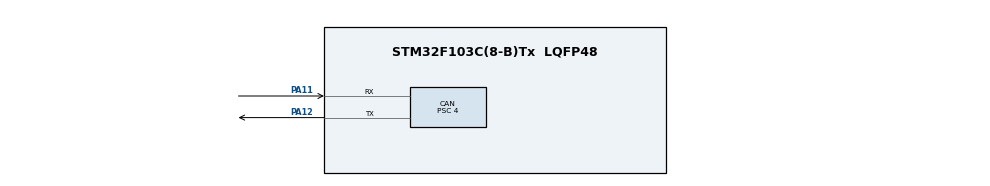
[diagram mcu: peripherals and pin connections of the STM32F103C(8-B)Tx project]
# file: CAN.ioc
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CAN.AutoBusOff=ENABLE
CAN.AutoRetransmission=ENABLE
CAN.BS1=CAN_BS1_13TQ
CAN.BS2=CAN_BS2_2TQ
CAN.CalculateBaudRate=125000
CAN.CalculateTimeBit=8000
CAN.CalculateTimeQuantum=500.0
CAN.Prescaler=4
CAN.SJW=CAN_SJW_1TQ
Mcu.Family=STM32F1
Mcu.Name=STM32F103C(8-B)Tx
Mcu.Package=LQFP48
NVIC.PriorityGroup=NVIC_PRIORITYGROUP_4
PA11.Mode=CAN_Activate
PA11.Signal=CAN_RX
PA12.Mode=CAN_Activate
PA12.Signal=CAN_TX
PA13.Mode=Serial_Wire
PA13.Signal=SYS_JTMS-SWDIO
PA14.Mode=Serial_Wire
PA14.Signal=SYS_JTCK-SWCLK
ProjectManager.HeapSize=0x200
ProjectManager.StackSize=0x400
ProjectManager.TargetToolchain=CMake
RCC.APB1Freq_Value=8000000
RCC.APB2Freq_Value=8000000
board=custom

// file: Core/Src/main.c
/* USER CODE BEGIN Header */
/**
  ******************************************************************************
  * @file           : main.c
  * @brief          : Main program body
  ******************************************************************************
  * @attention
  *
  * Copyright (c) 2026 STMicroelectronics.
  * All rights reserved.
  *
  * This software is licensed under terms that can be found in the LICENSE file
  * in the root directory of this software component.
  * If no LICENSE file comes with this software, it is provided AS-IS.
  *
  ******************************************************************************
  */
/* USER CODE END Header */
#include "main.h"

/* USER CODE BEGIN Includes */
#include "log.h"

/* USER CODE END Includes */

/* USER CODE BEGIN PD */
#define CAN_TX_ID 0x200U
#define CAN_RX_ID 0x201U
#define CAN_TX_PERIOD_MS 1000U

/* USER CODE END PD */

CAN_HandleTypeDef hcan;

/* USER CODE BEGIN PV */
static uint8_t message_number;
static uint32_t last_recovery_ms;
static uint32_t last_tx_ms;
static uint8_t bus_off_reported;

/* USER CODE END PV */

void SystemClock_Config(void);
static void MX_GPIO_Init(void);
static void MX_CAN_Init(void);
/* USER CODE BEGIN PFP */
static void CAN_ConfigureAndStart(void);
static void CAN_Service(void);
static void CAN_LogFrame(const char *direction, uint32_t id, uint32_t dlc,
                         const uint8_t *data);

/* USER CODE END PFP */

int main(void)
{

  /* MCU Configuration--------------------------------------------------------*/

  /* Reset of all peripherals, Initializes the Flash interface and the Systick. */
  HAL_Init();

  /* USER CODE BEGIN Init */
  log_init();
  log_println("[BOOT] STM32 CAN demo");

  /* USER CODE END Init */

  /* Configure the system clock */
  SystemClock_Config();

  /* Initialize all configured peripherals */
  MX_GPIO_Init();
  MX_CAN_Init();
  /* USER CODE BEGIN 2 */
  CAN_ConfigureAndStart();
  log_println("[CAN] started 125 kbit/s, TX=0x200 RX=0x201, period=1000 ms");

  /* USER CODE END 2 */

  /* Infinite loop */
  while (1)
  {

    /* USER CODE BEGIN 3 */
    CAN_Service();
  }
  /* USER CODE END 3 */
}

void SystemClock_Config(void)
{
  RCC_OscInitTypeDef RCC_OscInitStruct = {0};
  RCC_ClkInitTypeDef RCC_ClkInitStruct = {0};

  /** Initializes the RCC Oscillators according to the specified parameters
  * in the RCC_OscInitTypeDef structure.
  */
  RCC_OscInitStruct.OscillatorType = RCC_OSCILLATORTYPE_HSI;
  RCC_OscInitStruct.HSIState = RCC_HSI_ON;
  RCC_OscInitStruct.HSICalibrationValue = RCC_HSICALIBRATION_DEFAULT;
  RCC_OscInitStruct.PLL.PLLState = RCC_PLL_NONE;
  if (HAL_RCC_OscConfig(&RCC_OscInitStruct) != HAL_OK)
  {
    Error_Handler();
  }

  /** Initializes the CPU, AHB and APB buses clocks
  */
  RCC_ClkInitStruct.ClockType = RCC_CLOCKTYPE_HCLK|RCC_CLOCKTYPE_SYSCLK
                              |RCC_CLOCKTYPE_PCLK1|RCC_CLOCKTYPE_PCLK2;
  RCC_ClkInitStruct.SYSCLKSource = RCC_SYSCLKSOURCE_HSI;
  RCC_ClkInitStruct.AHBCLKDivider = RCC_SYSCLK_DIV1;
  RCC_ClkInitStruct.APB1CLKDivider = RCC_HCLK_DIV1;
  RCC_ClkInitStruct.APB2CLKDivider = RCC_HCLK_DIV1;

  if (HAL_RCC_ClockConfig(&RCC_ClkInitStruct, FLASH_LATENCY_0) != HAL_OK)
  {
    Error_Handler();
  }
}

static void MX_CAN_Init(void)
{

  hcan.Instance = CAN1;
  /* 8 MHz APB1 / (4 * (1 + 13 + 2)) = 125 kbit/s. */
  hcan.Init.Prescaler = 4;
  hcan.Init.Mode = CAN_MODE_NORMAL;
  hcan.Init.SyncJumpWidth = CAN_SJW_1TQ;
  hcan.Init.TimeSeg1 = CAN_BS1_13TQ;
  hcan.Init.TimeSeg2 = CAN_BS2_2TQ;
  hcan.Init.TimeTriggeredMode = DISABLE;
  hcan.Init.AutoBusOff = ENABLE;
  hcan.Init.AutoWakeUp = DISABLE;
  hcan.Init.AutoRetransmission = ENABLE;
  hcan.Init.ReceiveFifoLocked = DISABLE;
  hcan.Init.TransmitFifoPriority = DISABLE;
  if (HAL_CAN_Init(&hcan) != HAL_OK)
  {
    Error_Handler();
  }

}

static void MX_GPIO_Init(void)
{

  /* GPIO Ports Clock Enable */
  __HAL_RCC_GPIOA_CLK_ENABLE();

}

/* USER CODE BEGIN 4 */
static void CAN_ConfigureAndStart(void)
{
  CAN_FilterTypeDef filter = {0};

  /* 32-bit mask filter: standard data frame with ID 0x201 only. */
  filter.FilterBank = 0;
  filter.FilterMode = CAN_FILTERMODE_IDMASK;
  filter.FilterScale = CAN_FILTERSCALE_32BIT;
  filter.FilterIdHigh = (uint16_t)(CAN_RX_ID << 5);
  filter.FilterIdLow = 0;
  filter.FilterMaskIdHigh = (uint16_t)(0x7FFU << 5);
  filter.FilterMaskIdLow = 0x0006U; /* match IDE and RTR */
  filter.FilterFIFOAssignment = CAN_FILTER_FIFO0;
  filter.FilterActivation = ENABLE;
  if (HAL_CAN_ConfigFilter(&hcan, &filter) != HAL_OK)
  {
    log_print("[CAN] filter failed, HAL error=");
    log_print_u32_hex(HAL_CAN_GetError(&hcan));
    log_println("");
    Error_Handler();
  }
  log_print("[CAN] before start: PA11=");
  log_print_u32_dec(HAL_GPIO_ReadPin(GPIOA, GPIO_PIN_11));
  log_print(" MSR=");
  log_print_u32_hex(CAN1->MSR);
  log_print(" CAN_REMAP=");
  log_print_u32_hex(AFIO->MAPR & AFIO_MAPR_CAN_REMAP);
  log_print(" BTR=");
  log_print_u32_hex(CAN1->BTR);
  log_println("");
  if (HAL_CAN_Start(&hcan) != HAL_OK)
  {
    log_print("[CAN] start failed, HAL error=");
    log_print_u32_hex(HAL_CAN_GetError(&hcan));
    log_print(" PA11=");
    log_print_u32_dec(HAL_GPIO_ReadPin(GPIOA, GPIO_PIN_11));
    log_print(" MCR=");
    log_print_u32_hex(CAN1->MCR);
    log_print(" MSR=");
    log_print_u32_hex(CAN1->MSR);
    log_print(" ESR=");
    log_print_u32_hex(CAN1->ESR);
    log_println("");
    Error_Handler();
  }
}

static void CAN_Service(void)
{
  CAN_RxHeaderTypeDef rx;
  CAN_TxHeaderTypeDef tx = {0};
  uint8_t received[8] = {0};
  uint8_t payload[8];
  uint32_t mailbox;
  uint32_t now = HAL_GetTick();
  uint32_t dlc;

  /* HAL error flags are sticky; ESR reports the current bus-off state. */
  if ((hcan.Instance->ESR & CAN_ESR_BOFF) != 0U)
  {
    if (bus_off_reported == 0U)
    {
      log_print("[CAN] bus off, HAL error=");
      log_print_u32_hex(HAL_CAN_GetError(&hcan));
      log_println("");
      bus_off_reported = 1U;
    }
    if ((now - last_recovery_ms) >= 1000U)
    {
      last_recovery_ms = now;
      if (HAL_CAN_Stop(&hcan) == HAL_OK)
      {
        if (HAL_CAN_Start(&hcan) == HAL_OK)
        {
          log_println("[CAN] restart requested");
        }
        else
        {
          log_println("[CAN] restart failed");
        }
      }
    }
    return;
  }
  if (bus_off_reported != 0U)
  {
    log_println("[CAN] bus active again");
    bus_off_reported = 0U;
  }

  while (HAL_CAN_GetRxFifoFillLevel(&hcan, CAN_RX_FIFO0) != 0U)
  {
    if (HAL_CAN_GetRxMessage(&hcan, CAN_RX_FIFO0, &rx, received) != HAL_OK)
    {
      log_print("[CAN] RX failed, HAL error=");
      log_print_u32_hex(HAL_CAN_GetError(&hcan));
      log_println("");
      break;
    }
    CAN_LogFrame("RX", rx.IDE == CAN_ID_STD ? rx.StdId : rx.ExtId,
                 rx.DLC, received);
  }

  if ((now - last_tx_ms) < CAN_TX_PERIOD_MS)
  {
    return;
  }
  last_tx_ms = now;
  if (HAL_CAN_GetTxMailboxesFreeLevel(&hcan) == 0U)
  {
    log_print("[CAN] TX mailboxes full; frame skipped, ESR=");
    log_print_u32_hex(CAN1->ESR);
    log_print(" TSR=");
    log_print_u32_hex(CAN1->TSR);
    log_print(" PA11=");
    log_print_u32_dec(HAL_GPIO_ReadPin(GPIOA, GPIO_PIN_11));
    log_println("");
    return;
  }

  payload[0] = 'h';
  payload[1] = 'e';
  payload[2] = 'l';
  payload[3] = 'l';
  payload[4] = 'o';
  payload[5] = ' ';
  if (message_number >= 10U)
  {
    payload[6] = (uint8_t)('0' + message_number / 10U);
    payload[7] = (uint8_t)('0' + message_number % 10U);
    dlc = 8U;
  }
  else
  {
    payload[6] = (uint8_t)('0' + message_number);
    dlc = 7U;
  }
  tx.StdId = CAN_TX_ID;
  tx.IDE = CAN_ID_STD;
  tx.RTR = CAN_RTR_DATA;
  tx.DLC = dlc;
  if (HAL_CAN_AddTxMessage(&hcan, &tx, payload, &mailbox) == HAL_OK)
  {
    CAN_LogFrame("TX queued", tx.StdId, tx.DLC, payload);
    message_number = (uint8_t)((message_number + 1U) % 100U);
  }
  else
  {
    log_print("[CAN] TX failed, HAL error=");
    log_print_u32_hex(HAL_CAN_GetError(&hcan));
    log_println("");
  }
}

static void CAN_LogFrame(const char *direction, uint32_t id, uint32_t dlc,
                         const uint8_t *data)
{
  uint32_t i;

  log_print("[CAN] ");
  log_print(direction);
  log_print(" id=");
  log_print_u32_hex(id);
  log_print(" dlc=");
  log_print_u32_dec(dlc);
  log_print(" text=\"");
  for (i = 0U; i < dlc && i < 8U; ++i)
  {
    char character[2] = {(char)data[i], '\0'};
    log_print(character);
  }
  log_print("\"");
  log_println("");
}

/* USER CODE END 4 */

void Error_Handler(void)
{
  /* USER CODE BEGIN Error_Handler_Debug */
  log_print("[ERROR] fatal, CAN HAL error=");
  log_print_u32_hex(HAL_CAN_GetError(&hcan));
  log_println("");
  __disable_irq();
  while (1)
  {
  }
  /* USER CODE END Error_Handler_Debug */
}
